# R40 register map
Vendor: Allwinner; Series: R40; File version: 0.1
CPU: CA7 0, little endian, MPU, FPU, double-precision FPU, 0 interrupt priority bits
Registers are 32-bit, read-write, reset 0x0 unless marked. A register's access mark holds for its fields unless they carry their own. Offsets are from the block's base; [hi:lo] are bit positions; lines under a group give offsets from that group; {n}, {i} and the like mark numbered series; 'fields as' and 'values as' point back to an identical list.

## TCON_TOP
Base 0x01C70000
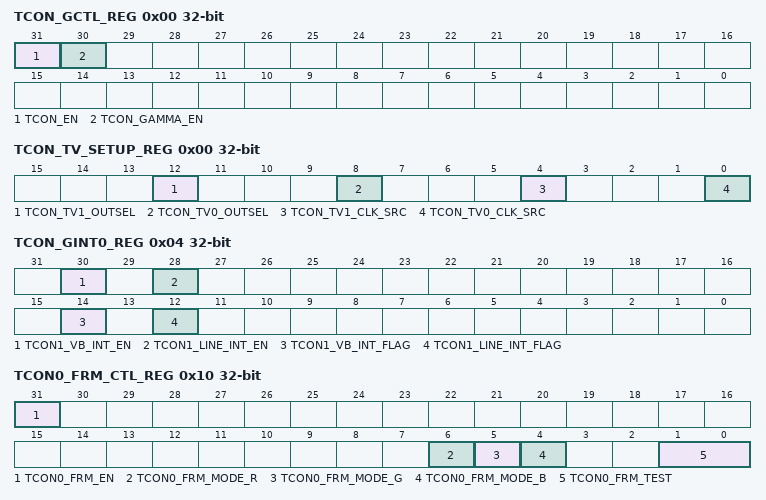
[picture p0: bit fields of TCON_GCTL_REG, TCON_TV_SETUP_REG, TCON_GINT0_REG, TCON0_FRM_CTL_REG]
0x00 TCON_GCTL_REG — TCON Global Control Register
  [31] TCON_EN — 0: Disable 1: Enable When it`s disabled, the module will be reset to idle state.
    0=Disable; 1=Enable When it`s disabled, the module will be reset to idle state
  [30] TCON_GAMMA_EN — 0: Disable 1: Enable
    0=Disable; 1=Enable
0x00 TCON_TV_SETUP_REG
  [12] TCON_TV1_OUTSEL — 0: LCD1 output to GPIOH 1: TV1 output to GPIOH
    0=LCD1 (LCD1 output to GPIOH); 1=TV1 (TV1 output to GPIOH)
  [8] TCON_TV0_OUTSEL — 0: LCD0 output to GPIOD 1: TV0 output to GPIOD
    0=LCD0 (LCD0 output to GPIOD); 1=TV0 (TV0 output to GPIOD)
  [4] TCON_TV1_CLK_SRC — 0: Clock from CCU 1: Clock from TVE1
    0=Clock_from_CCU; 1=Clock_from_TVE1
  [0] TCON_TV0_CLK_SRC — 0: Clock from CCU 1: Clock from TVE0
    0=Clock_from_CCU; 1=Clock_from_TVE0
0x04 TCON_GINT0_REG — TCON Global Interrupt Register0
  [30] TCON1_VB_INT_EN — 0: Disable 1: Enable
    0=Disable; 1=Enable
  [28] TCON1_LINE_INT_EN — 0: Disable 1: Enable
    0=Disable; 1=Enable
  [14] TCON1_VB_INT_FLAG — Asserted during vertical no-display period every frame. Write 0 to clear it.
  [12] TCON1_LINE_INT_FLAG — Trigger when SY1 match the current TCON1 scan line Write 0 to clear it.
0x08 TCON_GINT1_REG — TCON Global Interrupt Register1
  [11:0] TCON1_LINE_INT_NUM — scan line for TCON1 line trigger(including inactive lines) Setting it for the specified line for trigger 1. Note: SY1 is writable only when LINE_TRG1 disable.
0x10 TCON0_FRM_CTL_REG — TCON FRM Control Register
  [31] TCON0_FRM_EN — 0:Disable 1:Enable
  [6] TCON0_FRM_MODE_R — 0: 6bit frm output 1: 5bit frm output
    0=6bit frm output; 1=5bit frm output
  [5] TCON0_FRM_MODE_G — 0: 6bit frm output 1: 5bit frm output
    0=6bit frm output; 1=5bit frm output
  [4] TCON0_FRM_MODE_B — 0: 6bit frm output 1: 5bit frm output
    0=6bit frm output; 1=5bit frm output
  [1:0] TCON0_FRM_TEST — 00: FRM 01: half 5/6bit, half FRM 10: half 8bit, half FRM 11: half 8bit, half 5/6bit
{0x14+4i} TCON0_FRM_SEED_REG[{i}] (i=0..5) — TCON FRM Seed Register (N=0,1,2,3,4,5)
  [24:0] SEED_VALUE — N=0: Pixel_Seed_R N=1: Pixel_Seed_G N=2: Pixel_Seed_B N=3: Line_Seed_R N=4: Line_Seed_G N=5: Line_Seed_B Note: Avoid to set it to 0
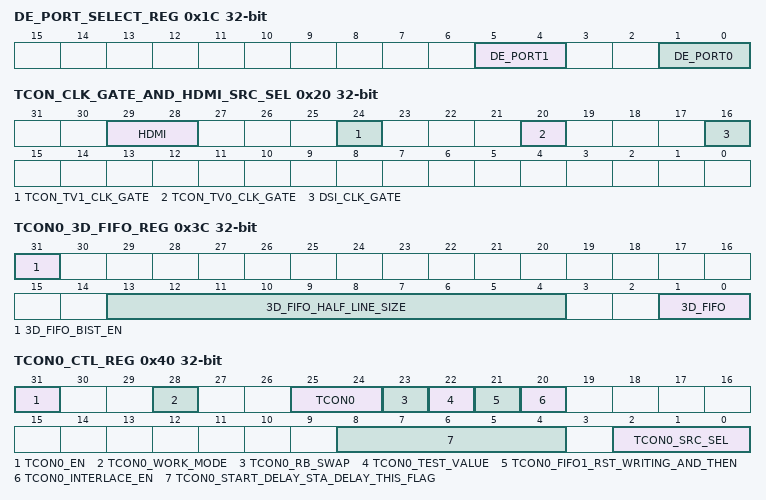
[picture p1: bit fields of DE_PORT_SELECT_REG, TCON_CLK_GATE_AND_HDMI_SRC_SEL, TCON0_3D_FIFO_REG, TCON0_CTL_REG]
0x1C DE_PORT_SELECT_REG
  [5:4] DE_PORT1 — PERH Select. 00:TCON_LCD0 01:TCON_LCD1 10:TCON_TV0 11:TCON_TV1 Note: The priority of DE0 is higher than DE1. If TCON_LCD0 selects DE0 and DE1 as source at the same time, then DE0 will be used for the source of TCON_LCD0.
  [1:0] DE_PORT0 — PERH Select. 00:TCON_LCD0 01:TCON_LCD1 10:TCON_TV0 11:TCON_TV1 Note: The priority of DE0 is higher than DE1. If TCON_LCD0 selects DE0 and DE1 as source at the same time, then DE0 will be used for the source of TCON_LCD0.
0x20 TCON_CLK_GATE_AND_HDMI_SRC_SEL
  [29:28] HDMI — Source select. 00:Disable 01:TCON_TV0 10:TCON_TV1 11:Reserved
  [24] TCON_TV1_CLK_GATE — 0:Disable clk 1:Enable clk
  [20] TCON_TV0_CLK_GATE — 0:Disable clk 1:Enable clk
  [16] DSI_CLK_GATE — 0:Disable clk 1:Enable clk
{0x2C+4i} TCON0_FRM_TAB_REG[{i}] (i=0..3) — TCON FRM Table Register (N=0,1,2,3)
  [31:0] FRM_TABLE_VALUE
0x3C TCON0_3D_FIFO_REG — TCON0 3D FIFO Register
  [31] 3D_FIFO_BIST_EN — 0: Disable 1: Enable
    0=Disable; 1=Enable
  [13:4] 3D_FIFO_HALF_LINE_SIZE — The number of data in half line=3D_FIFO_HALF_LINE_SIZE+1. Only valid when 3D_FIFO_SETTING set as 2
  [1:0] 3D_FIFO — 00: by pass 01: used as normal FIFO 10: used as 3D interlace FIFO 11: reserved
0x40 TCON0_CTL_REG — TCON0 Control Register
  [31] TCON0_EN — TCON0_EN 0: Disable 1: Enable Note: It executes at the beginning of the first blank line of TCON0 timing.
    0=Disable; 1=Enable Note: It executes at the beginning of the first blank line of TCON0 timing
  [28] TCON0_WORK_MODE — TCON0_WORK_MODE 0: Normal 1: Dynamic freq
    0=Normal; 1=Dynamic freq
  [25:24] TCON0 — TCON0_IF 00: HV(Sync+DE) 01: 8080 I/F 1x: Reservd
    0=HV_openingparen_Sync_plus_DE_closingparen_ (HV(Sync+DE)); 1=8080 I/F; 2=Reservd
  [23] TCON0_RB_SWAP — TCON0_RB_SWAP 0: Default 1: Swap RED and BLUE data at FIFO1
    0=Default; 1=Swap RED and BLUE data at FIFO1
  [22] TCON0_TEST_VALUE — TCON0_TEST_VALUE 0:all 0s 1:all 1s
  [21] TCON0_FIFO1_RST_WRITING_AND_THEN — TCON0_FIFO1_RST Writing 1 and then 0 at this bit will reset FIFO 1 Note: 1 holding time must more than 1 DCLK
  [20] TCON0_INTERLACE_EN — TCON0_INTERLACE_EN 0:Disable 1:Enable This flag is valid only when TCON0_EN = 1
  [8:4] TCON0_START_DELAY_STA_DELAY_THIS_FLAG — TCON0_START_DELAY STA delay This flag is valid only when TCON0_EN = 1
  [2:0] TCON0_SRC_SEL — TCON0_SRC_SEL 000: DE0 001: Color Check 010: Grayscale Check 011: Black by White Check 100: Test Data all 0 101: Test Data all 1 111: Gridding Check
0x40 TCON1_SRC_CTL_REG
  [2:0] TCON1_SRC_SEL — 000: DE 001: Color Check 010: Grayscale Check 011: Black by White Check 100: Reserved 101: Reserved 111: Gridding Check
    0=DE; 1=Color Check; 2=Grayscale Check; 3=Black by White Check; 7=Gridding Check
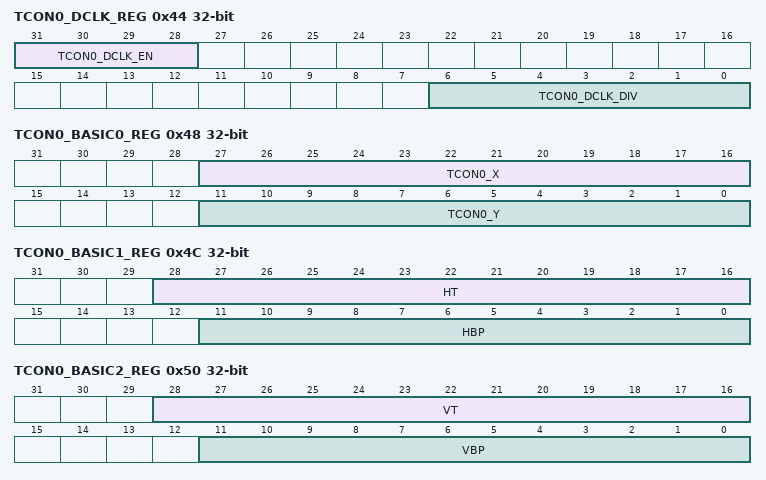
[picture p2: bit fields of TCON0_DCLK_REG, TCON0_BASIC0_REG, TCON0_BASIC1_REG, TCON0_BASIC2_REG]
0x44 TCON0_DCLK_REG — TCON0 Data Clock Register
  [31:28] TCON0_DCLK_EN — LCLK_EN[3:0] :TCON0 clock enable 4'h0, 'h4,4'h6,4'ha7:dclk_en=0;dclk1_en=0;dclk2_en=0;dclkm2_en=0; 4'h1: dclk_en = 1; dclk1_en = 0; dclk2_en = 0; dclkm2_en = 0; 4'h2: dclk_en = 1; dclk1_en = 0; dclk2_en = 0; dclkm2_en = 1; 4'h3: dclk_en = 1; dclk1_en = 1; dclk2_en = 0; dclkm2_en = 0; 4'h5: dclk_en = 1; dclk1_en = 0; dclk2_en = 1; dclkm2_en = 0; 4'h8,4'h9,4'ha,4'hb,4'hc,4'hd,4'he,4'hf: dclk_en = 1; dclk1_en = 1; dclk2_en = 1; dclkm2_en = 1;
  [6:0] TCON0_DCLK_DIV — Tdclk = Tsclk * DCLKDIV If dclk1&dclk2 used DCLKDIV >=6 If dclk only DCLKDIV >=1
0x48 TCON0_BASIC0_REG — TCON0 Basic Timing Register0
  [27:16] TCON0_X — Panel width is X+1
  [11:0] TCON0_Y — Panel height is Y+1
0x4C TCON0_BASIC1_REG — TCON0 Basic Timing Register1
  [28:16] HT — Thcycle = (HT+1) * Tdclk Computation 1) parallel:HT = X + BLANK Limitation: 1) parallel :HT >= (HBP +1) + (X+1) +2 2) serial 1: HT >= (HBP +1) + (X+1) *3+2 3) serial 2: HT >= (HBP +1) + (X+1) *3/2+2
  [11:0] HBP — horizontal back porch (in dclk) Thbp = (HBP +1) * Tdclk
0x50 TCON0_BASIC2_REG — TCON0 Basic Timing Register2
  [28:16] VT — TVT = (VT)/2 * Thsync Note: VT/2 >= (VBP+1 ) + (Y+1) +2
  [11:0] VBP — Tvbp = (VBP +1) * Thsync
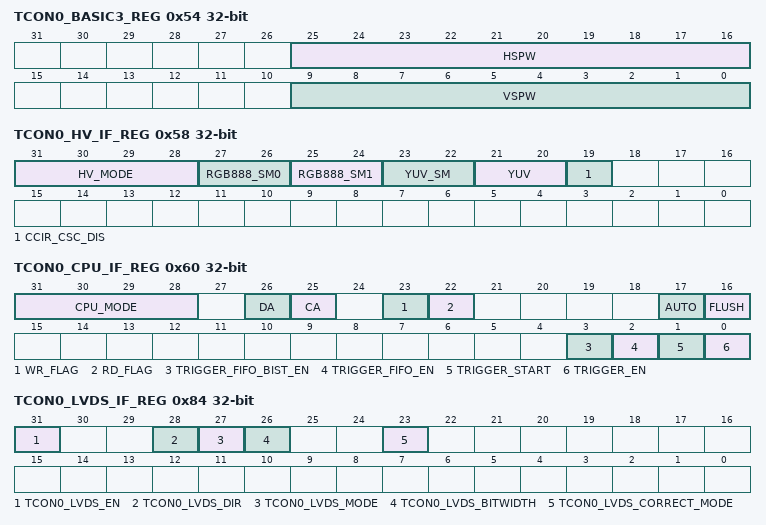
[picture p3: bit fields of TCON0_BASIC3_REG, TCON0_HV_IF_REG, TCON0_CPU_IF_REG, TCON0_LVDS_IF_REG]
0x54 TCON0_BASIC3_REG — TCON0 Basic Timing Register3
  [25:16] HSPW — Thspw = (HSPW+1) * Tdclk Note: HT> (HSPW+1)
  [9:0] VSPW — Tvspw = (VSPW+1) * Thsync Note: VT/2 > (VSPW+1)
0x58 TCON0_HV_IF_REG — TCON0 HV Panel Interface Register
  [31:28] HV_MODE — 0000: 24bit/1cycle parallel mode 1000: 8bit/3cycle RGB serial mode(RGB888) 1010: 8bit/4cycle Dummy RGB(DRGB) 1011: 8bit/4cycle RGB Dummy(RGBD) 1100: 8bit/2cycle YUV serial mode(CCIR656)
    0=_24bit_slash_1cycle_parallel_mode (24bit/1cycle parallel mode); 8=_8bit_slash_3cycle_RGB (8bit/3cycle RGB serial mode(RGB888)); 10=_8bit_slash_4cycle_Dummy (8bit/4cycle Dummy RGB(DRGB)); 11=_8bit_slash_4cycle_RGB (8bit/4cycle RGB Dummy(RGBD)); 12=_8bit_slash_2cycle_YUV (8bit/2cycle YUV serial mode(CCIR656))
  [27:26] RGB888_SM0 — serial RGB888 mode output sequence at odd lines of the panel (line 1, 3, 5, 7...) 00: R→G→B 01: B→R→G 10: G→B→R 11: R→G→B
  [25:24] RGB888_SM1 — serial RGB888 mode output sequence at even lines of the panel (line 2, 4, 6, 8...) 00: R→G→B 01: B→R→G 10: G→B→R 11: R→G→B
  [23:22] YUV_SM — serial YUV mode output sequence 2-pixel-pair of every scan line 00: YUYV 01: YVYU 10: UYVY 11: VYUY
    0=YUYV; 1=YVYU; 2=UYVY; 3=VYUY
  [21:20] YUV — EAV/SAV F LINE DELAY 00:F toggle right after active video line 01:delay 2 line(CCIR PAL) 10:delay 3 line(CCIR NTSC) 11:reserved
  [19] CCIR_CSC_DIS — 0: Enable 1: Disable Only valid when HV mode is `1100`, select `0` TCON convert source from RGB to YUV
    0=Enable; 1=Disable Only valid when HV mode is `1100`, select `0` TCON convert source from RGB to YUV
0x60 TCON0_CPU_IF_REG — TCON0 CPU Panel Interface Register
  [31:28] CPU_MODE — 0000: 18bit/256K mode 0010: 16bit mode0 0100: 16bit mode1 0110: 16bit mode2 1000: 16bit mode3 1010: 9bit mode 1100: 8bit 256K mode 1110: 8bit 65K mode xxx1: 24bit for DSI
    0=_18bit_slash_256K_mode (18bit/256K mode); 2=_16bit_mode0; 4=_16bit_mode1; 6=_16bit_mode2; 8=_16bit_mode3; 10=_9bit_mode; 12=_8bit_256K_mode; 14=_8bit_65K_mode; 1=24bit for DSI
  [26] DA — pin A1 value in 8080 mode auto/flash states
  [25] CA — pin A1 value in 8080 mode WR/RD execute
  [23] WR_FLAG ro — 0:Write operation is finishing 1:Write operation is pending
  [22] RD_FLAG ro — 0:Read operation is finishing 1:Read operation is pending
  [17] AUTO — auto Transfer Mode: If it is 1, all the valid data during this frame are written to panel. Note: This bit is sampled by Vsync
  [16] FLUSH — direct transfer mode If it is enabled, FIFO1 is regardless of the HV timing, pixels data keep being transferred unless the input FIFO was empty. Data output rate control by DCLK.
  [3] TRIGGER_FIFO_BIST_EN — 0: Disable 1: Enable Entry addr is 0xFF8
    0=Disable; 1=Enable Entry addr is 0xFF8
  [2] TRIGGER_FIFO_EN — 0:Enable 1:Disable
  [1] TRIGGER_START write-1-sets — Write `1` to start a frame flush, writing`0` has no effect. This flag indicated frame flush is running. Software must make sure that write `1` only when this flag is `0`.
  [0] TRIGGER_EN — 0: Trigger mode disable 1: Trigger mode enable
    0=disable (Trigger mode disable); 1=enable (Trigger mode enable)
0x64 TCON0_CPU_WRITE_REG — TCON0 CPU Panel Write Data Register
  [23:0] DATA_WRITE wo — Data write on 8080 bus, launch a write operation on 8080 bus
0x68 TCON0_CPU_RD0_REG — TCON0 CPU Panel Read Data Register0
  [23:0] DATA_READ0 ro — Data read on 8080 bus, launch a new read operation on 8080 bus
0x6C TCON0_CPU_RD1_REG — TCON0 CPU Panel Read Data Register1
  [23:0] DATA_READ1 ro — Data_READ1 Data read on 8080 bus, without a new read operation on 8080 bus
0x84 TCON0_LVDS_IF_REG
  [31] TCON0_LVDS_EN — 0: Disable 1: Enable
    0=Disable; 1=Enable
  [28] TCON0_LVDS_DIR — 1: Normal 2: Reversed Note: LVDS direction
    1=Normal
  [27] TCON0_LVDS_MODE — 0: NS mode 1: JEIDA mode
    0=NS_mode; 1=JEIDA_mode
  [26] TCON0_LVDS_BITWIDTH — 0: 24bit 1: 18bit
    0=_24bit; 1=_18bit
  [23] TCON0_LVDS_CORRECT_MODE — 0: Mode0 1: Mode1
    0=Mode0; 1=Mode1
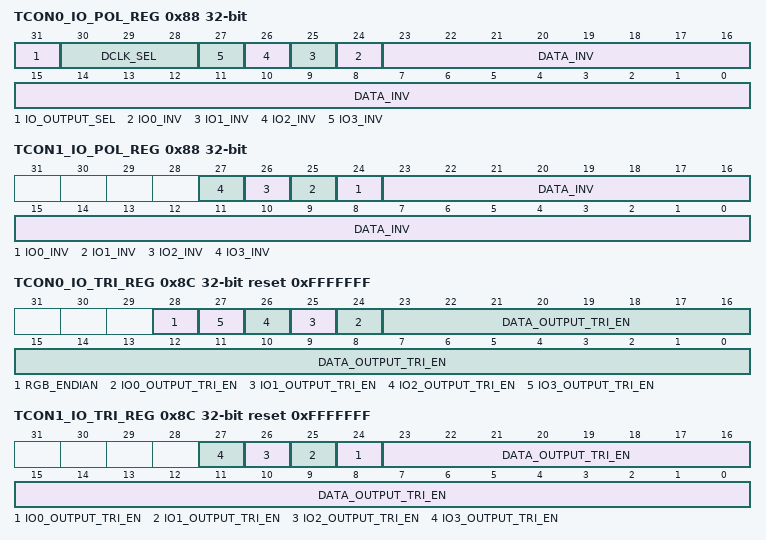
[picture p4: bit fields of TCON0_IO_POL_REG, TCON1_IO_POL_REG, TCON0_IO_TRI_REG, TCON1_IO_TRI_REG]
0x88 TCON0_IO_POL_REG — TCON0 IO Polarity Register
  [31] IO_OUTPUT_SEL — 0: normal output 1: register output when set as `1`, d*23:0+, io0, io1,io3 sync to dclk
    0=normal output; 1=register output when set as `1`, d*23:0+, io0, io1,io3 sync to dclk
  [30:28] DCLK_SEL — 000: used DCLK0(normal phase offset) 001: used DCLK1(1/3 phase offset) 010: used DCLK2(2/3 phase offset) 101: DCLK0/2 phase 0 100: DCLK0/2 phase 90 Others: Reserved
    0=used_DCLK0_openingparen_normal_phase (used DCLK0(normal phase offset)); 1=used_DCLK1_openingparen_1_slash_3_phase (used DCLK1(1/3 phase offset)); 2=used_DCLK2_openingparen_2_slash_3_phase (used DCLK2(2/3 phase offset)); 5=DCLK0_slash_2_phase_0 (DCLK0/2 phase 0); 4=DCLK0_slash_2_phase_90 (DCLK0/2 phase 90 Others: Reserved)
  [n+24] IO{n}_INV (n=0..3) — 0: not invert 1: invert
    0=not_invert; 1=invert
  [23:0] DATA_INV — TCON0 output port D[23:0] polarity control, with independent bit control: 0s: normal polarity 1s: invert the specify output
0x88 TCON1_IO_POL_REG — TCON1 IO Polarity Register
  [n+24] IO{n}_INV (n=0..3) — 0: not invert 1: invert
    0=not_invert; 1=invert
  [23:0] DATA_INV — TCON1 output port D[23:0] polarity control, with independent bit control: 0s: normal polarity 1s: invert the specify output
0x8C TCON0_IO_TRI_REG reset 0xFFFFFFF — TCON0 IO Control Register
  [28] RGB_ENDIAN — 0: Normal 1: Bits_invert
    0=Normal; 1=Bits_invert
  [n+24] IO{n}_OUTPUT_TRI_EN (n=0..3) — 1: Disable 0: Enable
    1=Disable; 0=Enable
  [23:0] DATA_OUTPUT_TRI_EN — TCON0 output port D[23:0] output enable, with independent bit control: 1s: Disable 0s: Enable
0x8C TCON1_IO_TRI_REG reset 0xFFFFFFF — TCON1 IO Control Register
  [n+24] IO{n}_OUTPUT_TRI_EN (n=0..3) — 1: Disable 0: Enable
    1=Disable; 0=Enable
  [23:0] DATA_OUTPUT_TRI_EN — TCON1 output port D[23:0] output enable, with independent bit control: 1s: Disable 0s: Enable
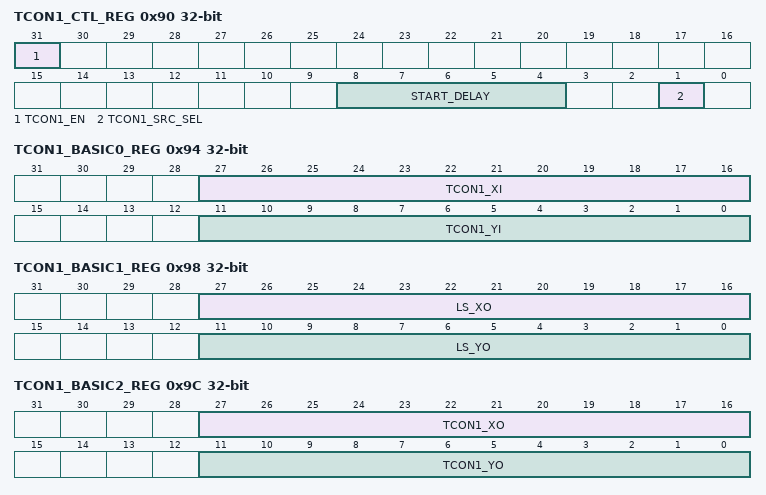
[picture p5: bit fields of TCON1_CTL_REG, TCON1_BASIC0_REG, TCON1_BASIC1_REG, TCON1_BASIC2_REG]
0x90 TCON1_CTL_REG — TCON1 Control Register
  [31] TCON1_EN — 0: Disable 1: Enable
    0=Disable; 1=Enable
  [8:4] START_DELAY — This is for DE0 and DE1
  [1] TCON1_SRC_SEL — 0: Reserved 1: BLUE data(FIFO2 disable, RGB=0000FF) Note The priority of the bit is higher than .
    1=BLUE (BLUE data(FIFO2 disable, RGB=0000FF) Note The priority of the bit is higher than .)
0x94 TCON1_BASIC0_REG — TCON1 Basic Timing Register0
  [27:16] TCON1_XI — source width is X+1
  [11:0] TCON1_YI — source height is Y+1
0x98 TCON1_BASIC1_REG — TCON1 Basic Timing Register1
  [27:16] LS_XO — width is LS_XO+1
  [11:0] LS_YO — width is LS_YO+1 This version LS_YO = TCON1_YI
0x9C TCON1_BASIC2_REG — TCON1 Basic Timing Register2
  [27:16] TCON1_XO — width is TCON1_XO+1
  [11:0] TCON1_YO — height is TCON1_YO+1
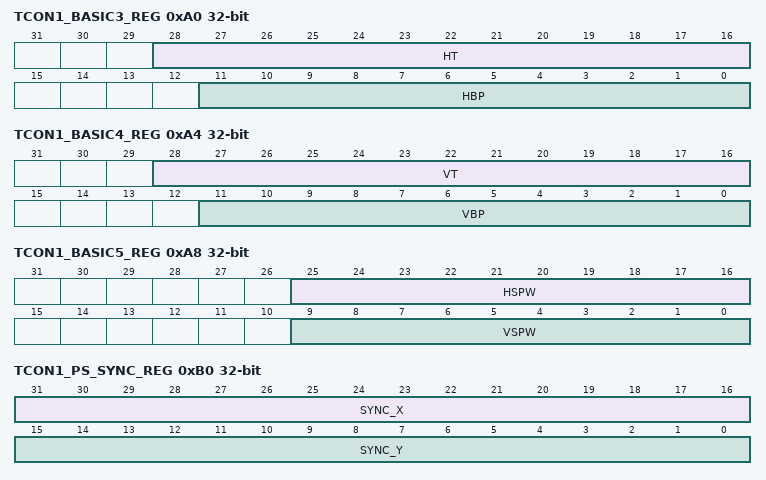
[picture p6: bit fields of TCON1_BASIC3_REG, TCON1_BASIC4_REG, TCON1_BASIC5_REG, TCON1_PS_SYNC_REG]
0xA0 TCON1_BASIC3_REG — TCON1 Basic Timing Register3
  [28:16] HT — horizontal total time Thcycle = (HT+1) * Thdclk
  [11:0] HBP — horizontal back porch Thbp = (HBP +1) * Thdclk
0xA4 TCON1_BASIC4_REG — TCON1 Basic Timing Register4
  [28:16] VT — horizontal total time (in HD line) Tvt = VT/2 * Th
  [11:0] VBP — horizontal back porch (in HD line) Tvbp = (VBP +1) * Th
0xA8 TCON1_BASIC5_REG — TCON1 Basic Timing Register5
  [25:16] HSPW — horizontal Sync Pulse Width (in dclk) Thspw = (HSPW+1) * Tdclk Note: HT > (HSPW+1)
  [9:0] VSPW — vertical Sync Pulse Width (in lines) Tvspw = (VSPW+1) * Th Note: VT/2 > (VSPW+1)
0xB0 TCON1_PS_SYNC_REG — TCON1 Sync Register
  [31:16] SYNC_X, [15:0] SYNC_Y
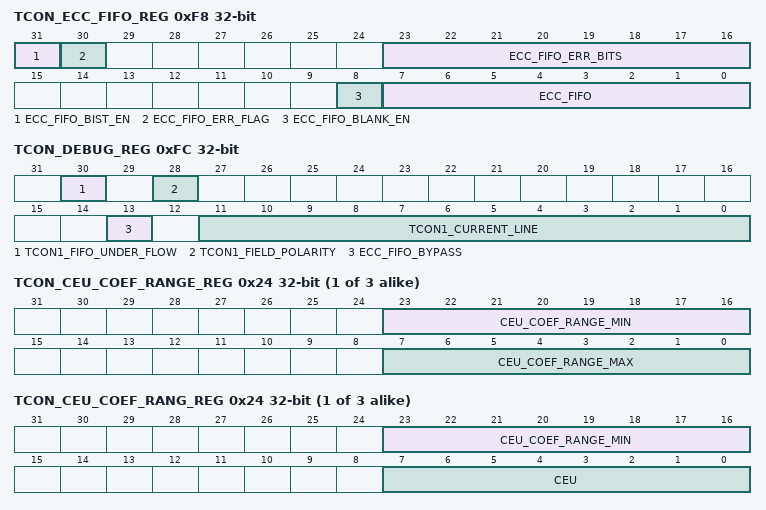
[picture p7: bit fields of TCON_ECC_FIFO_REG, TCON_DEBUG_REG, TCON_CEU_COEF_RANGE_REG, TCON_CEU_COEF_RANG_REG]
0xF8 TCON_ECC_FIFO_REG reset not defined — TCON ECC FIFO Register
  [31] ECC_FIFO_BIST_EN — 0: Disable 1: Enable
    0=Disable; 1=Enable
  [30] ECC_FIFO_ERR_FLAG
  [23:16] ECC_FIFO_ERR_BITS
  [8] ECC_FIFO_BLANK_EN — 0: Disable ecc function in blanking 1: Enable ecc function in blanking ECC function is tent to trigger in blanking area at hv mode, set `0` when in hv mode
    0=Disable ecc function in blanking; 1=Enable ecc function in blanking ECC function is tent to trigger in blanking area at hv mode, set `0` when in hv mode
  [7:0] ECC_FIFO — bit3 0:Enable 1:Disable
0xFC TCON_DEBUG_REG (reset mask 0x2000) — TCON Debug Register
  [30] TCON1_FIFO_UNDER_FLOW
  [28] TCON1_FIELD_POLARITY ro — 0: second field 1: first field
    0=second; 1=first
  [13] ECC_FIFO_BYPASS — 0: used 1: bypass
    0=used; 1=bypass
  [11:0] TCON1_CURRENT_LINE ro
0x100 TCON_CEU_CTL_REG — TCON CEU Control Register
  [31] CEU_EN — 0: bypass 1: enable
    0=bypass; 1=enable
{0x110+4i} TCON_CEU_COEF_MUL_REG_{i} (i=0..2) — N*0x04 TCON CEU Coefficient Register0 (N=0,1,2,4,5,6,8,9,10)
  [12:0] CEU_COEF_MUL_VALUE — signed 13bit value, range of (-16,16) N=0: Rr N=1: Rg N=2: Rb N=4: Gr N=5: Gg N=6: Gb N=8: Br N=9: Bg N=10: Bb
{0x11C+0xC*i} _N[{i}] (i=0..2) group
  0x00 TCON_CEU_COEF_ADD_REG — TCON CEU Coefficient Register1 (N=0,1,2)
    [18:0] CEU_COEF_ADD_VALUE — signed 19bit value, range of (-16384, 16384) N=0: Rc N=1: Gc N=2: Bc
  0x24 TCON_CEU_COEF_RANGE_REG
    [23:16] CEU_COEF_RANGE_MIN — unsigned 8bit value, range of [0,255]
    [7:0] CEU_COEF_RANGE_MAX — unsigned 8bit value, range of [0,255]
  0x24 TCON_CEU_COEF_RANG_REG — TCON CEU Coefficient Register2 (N=0,1,2)
    [23:16] CEU_COEF_RANGE_MIN — Unsigned 8bit value, range of [0,255]
    [7:0] CEU — COEF_RANGE_MAX Unsigned 8bit value, range of [0,255]
  0x1E8 TCON1_FILL_BEGIN_REG — TCON1 Fill Data Begin Register (N=0,1,2)
    [23:0] FILL_BEGIN
  0x1EC TCON1_FILL_END_REG — TCON1 Fill Data End Register (N=0,1,2)
    [23:0] FILL_END
  0x1F0 TCON1_FILL_DATA0_REG — TCON1 Fill Data Value Register (N=0,1,2)
    [23:0] FILL_VALUE
{0x110+4i} TCON_CEU_COEF_MUL_REG_{i} (i=4..6) — N*0x04 TCON CEU Coefficient Register0 (N=0,1,2,4,5,6,8,9,10)
  fields as TCON_CEU_COEF_MUL_REG_0
{0x110+4i} TCON_CEU_COEF_MUL_REG_{i} (i=8..10) — N*0x04 TCON CEU Coefficient Register0 (N=0,1,2,4,5,6,8,9,10)
  fields as TCON_CEU_COEF_MUL_REG_0
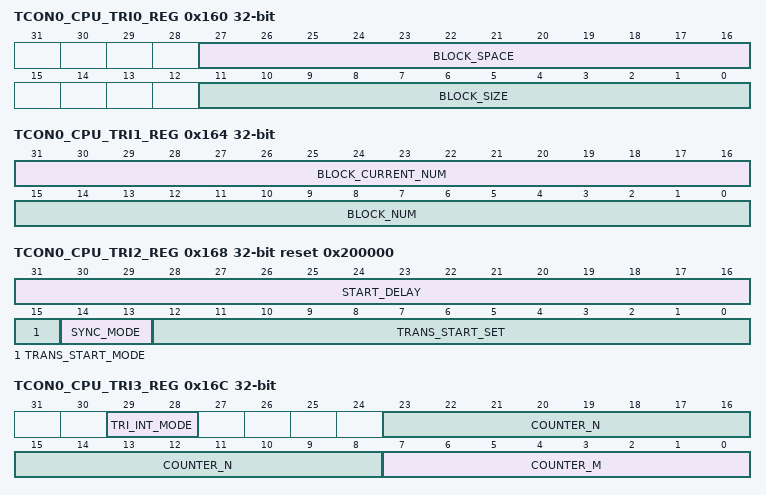
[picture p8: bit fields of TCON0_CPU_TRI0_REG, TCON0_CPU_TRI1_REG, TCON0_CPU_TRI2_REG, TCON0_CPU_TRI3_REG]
0x160 TCON0_CPU_TRI0_REG — TCON0 CPU Panel Trigger Register0
  [27:16] BLOCK_SPACE — should be set >20*pixel_cycle
  [11:0] BLOCK_SIZE
0x164 TCON0_CPU_TRI1_REG — TCON0 CPU Panel Trigger Register1
  [31:16] BLOCK_CURRENT_NUM ro, [15:0] BLOCK_NUM
0x168 TCON0_CPU_TRI2_REG reset 0x200000 — TCON0 CPU Panel Trigger Register2
  [31:16] START_DELAY — Tdly = (Start_Delay +1) * be_clk*8
  [15] TRANS_START_MODE — 0: ecc_fifo+tri_fifo 1: tri_fifo
    0=ecc_fifo_plus_tri_fifo (ecc_fifo+tri_fifo); 1=tri_fifo
  [14:13] SYNC_MODE — 0x: auto 10: 0 11: 1
    2=_0; 3=_1
  [12:0] TRANS_START_SET
0x16C TCON0_CPU_TRI3_REG — TCON0 CPU Panel Trigger Register3
  [29:28] TRI_INT_MODE — 00: disable 01: counter mode 10: te rising mode 11: te falling mode when set as 01, Tri_Counter_Int occur in cycle of (Count_N+1)×(Count_M+1)×4 dclk. when set as 10 or 11, io0 is map as TE input.
  [23:8] COUNTER_N
  [7:0] COUNTER_M
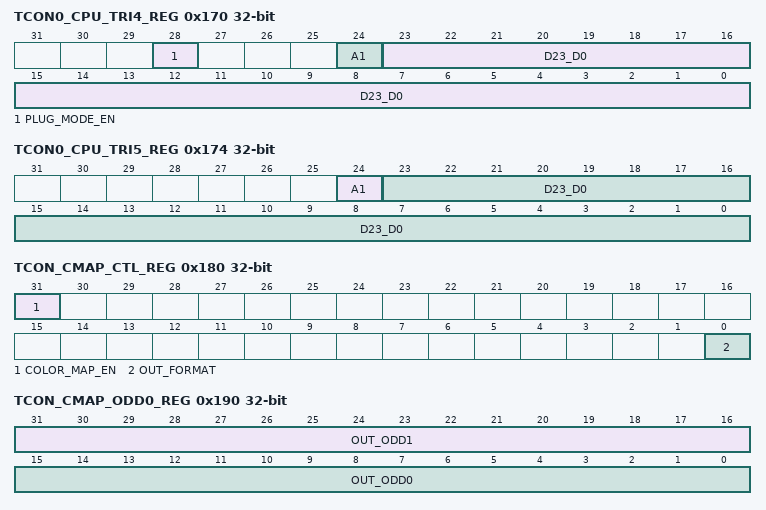
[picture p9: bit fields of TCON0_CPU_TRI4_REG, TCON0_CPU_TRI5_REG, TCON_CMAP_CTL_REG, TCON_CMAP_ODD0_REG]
0x170 TCON0_CPU_TRI4_REG — TCON0 CPU Panel Trigger Register4
  [28] PLUG_MODE_EN — 0: Disable 1: Enable
    0=Disable; 1=Enable
  [24] A1 — Valid in first Block
  [23:0] D23_D0 — Valid in first Block
0x174 TCON0_CPU_TRI5_REG — TCON0 CPU Panel Trigger Register5
  [24] A1 — Valid in Block except first
  [23:0] D23_D0 — Valid in Block except first
0x180 TCON_CMAP_CTL_REG — TCON Color Map Control register
  [31] COLOR_MAP_EN — 0: bypass 1: enable This module only work when X is divided by 4
    0=bypass; 1=enable This module only work when X is divided by 4
  [0] OUT_FORMAT — 0: 4 pixel output mode: Out0 -> Out1 -> Out2 -> Out3 1: 2 pixel output mode: Out0 -> Out1
    0=4 pixel output mode: Out0 -> Out1 -> Out2 -> Out3; 1=2 pixel output mode: Out0 -> Out1
0x190 TCON_CMAP_ODD0_REG — TCON Color Map Odd Line Register0
  [31:16] OUT_ODD1
  [15:0] OUT_ODD0 — bit15-12: Reserved bit11-08: Out_Odd0[23:16] bit07-04: Out_Odd0[15:8] bit03-00: Out_Odd0[7:0] 0x0: in_b0 0x1: in_g0 0x2: in_r0 0x3: Reserved 0x4: in_b1 0x5: in_g1 0x6: in_r1 0x7: Reserved 0x8: in_b2 0x9: in_g2GIC 0xa: in_r2 0xb: Reserved 0xc: in_b3 0xd: in_g3 0xe: in_r3 0xf: Reserved
    0=in_b0; 1=in_g0; 2=in_r0; 4=in_b1; 5=in_g1; 6=in_r1; 8=in_b2; 9=in_g2GIC 0xa: in_r2 0xb: Reserved 0xc: in_b3 0xd: in_g3 0xe: in_r3 0xf: Reserved
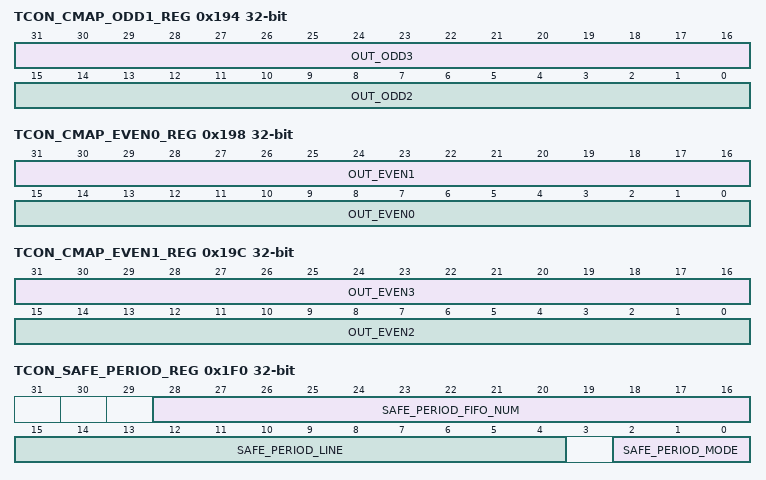
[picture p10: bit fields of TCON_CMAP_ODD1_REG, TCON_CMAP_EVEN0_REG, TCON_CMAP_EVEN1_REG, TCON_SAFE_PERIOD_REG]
0x194 TCON_CMAP_ODD1_REG — TCON Color Map Odd Line Register1
  [31:16] OUT_ODD3, [15:0] OUT_ODD2
0x198 TCON_CMAP_EVEN0_REG — TCON Color Map Even Line Register0
  [31:16] OUT_EVEN1, [15:0] OUT_EVEN0
0x19C TCON_CMAP_EVEN1_REG — TCON Color Map Even Line Register1
  [31:16] OUT_EVEN3, [15:0] OUT_EVEN2
0x1F0 TCON_SAFE_PERIOD_REG — TCON Safe Period Register
  [28:16] SAFE_PERIOD_FIFO_NUM
  [15:4] SAFE_PERIOD_LINE
  [2:0] SAFE_PERIOD_MODE — 000: unsafe 001: safe 010: safe at ecc_fifo_curr_num > safe_period_fifo_num 011: safe at 2 and safe at sync active 100: safe at line
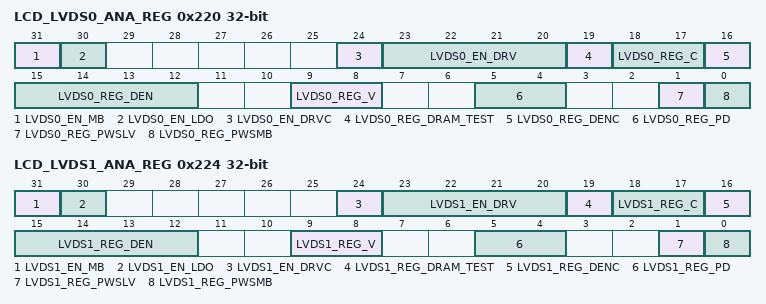
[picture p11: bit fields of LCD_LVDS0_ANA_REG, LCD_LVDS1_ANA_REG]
0x220 LCD_LVDS0_ANA_REG
  [31] LVDS0_EN_MB — Enable the bias circuit of the LVDS_Ana module
  [30] LVDS0_EN_LDO
  [24] LVDS0_EN_DRVC — Enable all circuits working when transmitting the data in channel clock of LVDS_tx0
  [23:20] LVDS0_EN_DRV — Enable all circuits working when transmitting the data in channel<3:0> of LVDS_tx0
  [19] LVDS0_REG_DRAM_TEST — 0:dram test clk disable 1:dram test clk enable
  [18:17] LVDS0_REG_C — Adjust current flowing through Rload of Rx to change the differential signals amplitude 00:250mV 01:300mV 10:350mV 11:400mV
  [16] LVDS0_REG_DENC — Choose data output or PLL test clock output in LVDS_tx
  [15:12] LVDS0_REG_DEN — Choose data output or PLL test clock output in LVDS_tx
  [9:8] LVDS0_REG_V — Adjust common mode voltage of the differential signals in five channels. single signal high level: 00:1.1V 01:1.19V 10:1.3V 11:1.43V
  [5:4] LVDS0_REG_PD — Fine adjust the slew rate of output data
  [1] LVDS0_REG_PWSLV — Adjust voltage amplitude of low power in LVDS_Ana
  [0] LVDS0_REG_PWSMB — Adjust voltage amplitude of mbias voltage reference in LVDS_Ana
0x224 LCD_LVDS1_ANA_REG
  [31] LVDS1_EN_MB — Enable the bias circuit of the LVDS_Ana module
  [30] LVDS1_EN_LDO
  [24] LVDS1_EN_DRVC — Enable all circuits working when transmitting the data in channel clock of LVDS_tx0
  [23:20] LVDS1_EN_DRV — Enable all circuits working when transmitting the data in channel<3:0> of LVDS_tx0
  [19] LVDS1_REG_DRAM_TEST — 0:dram test clk disable 1:dram test clk enable
  [18:17] LVDS1_REG_C — Adjust current flowing through Road of Rx to change the differential signals amplitude 00:250mV 01:300mV 10:350mV 11:400mV
  [16] LVDS1_REG_DENC — Choose data output or PLL test clock output in LVDS_tx
  [15:12] LVDS1_REG_DEN — Choose data output or PLL test clock output in LVDS_tx
  [9:8] LVDS1_REG_V — Adjust common mode voltage of the differential signals in five channels. single signal high level: 00:1.1V 01:1.19V 10:1.3V 11:1.43V
  [5:4] LVDS1_REG_PD — Fine adjust the slew rate of output data
  [1] LVDS1_REG_PWSLV — Adjust voltage amplitude of low power in LVDS_Ana
  [0] LVDS1_REG_PWSMB — Adjust voltage amplitude of mbias voltage reference in LVDS_Ana
0x300 TCON1_FILL_CTL_REG — TCON1 Fill Data Control Register
  [31] TCON1_FILL_EN — 0: bypass 1: enable
    0=bypass; 1=enable

## TCON_LCD0
Base 0x01C71000
Same registers: TCON_LCD1 0x01C72000
Registers as TCON_TOP, without TCON_TV_SETUP_REG, DE_PORT_SELECT_REG, TCON_CLK_GATE_AND_HDMI_SRC_SEL, TCON1_SRC_CTL_REG, TCON0_LVDS_IF_REG, TCON1_IO_POL_REG, TCON1_IO_TRI_REG, TCON1_CTL_REG, TCON1_BASIC{n}_REG (n=0..5), TCON1_PS_SYNC_REG, TCON_ECC_FIFO_REG, _N[*], LCD_LVDS0_ANA_REG, LCD_LVDS1_ANA_REG, TCON1_FILL_CTL_REG; these are added or differ:
{0x11C+0x10*i} _N[{i}] (i=0..2) group
  0x00 TCON_CEU_COEF_ADD_REG — TCON CEU Coefficient Register1 (N=0,1,2)
    [18:0] CEU_COEF_ADD_VALUE — signed 19bit value, range of (-16384, 16384) N=0: Rc N=1: Gc N=2: Bc
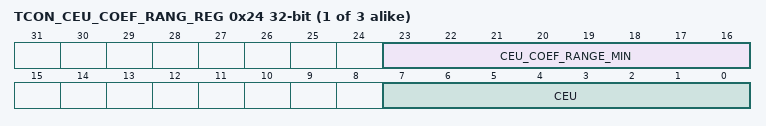
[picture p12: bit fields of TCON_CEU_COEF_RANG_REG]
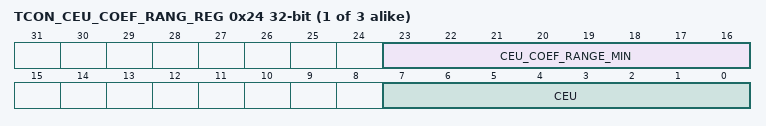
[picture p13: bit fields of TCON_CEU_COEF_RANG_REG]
  0x24 TCON_CEU_COEF_RANG_REG — TCON CEU Coefficient Register2 (N=0,1,2)
    [23:16] CEU_COEF_RANGE_MIN — Unsigned 8bit value, range of [0,255]
    [7:0] CEU — COEF_RANGE_MAX Unsigned 8bit value, range of [0,255]

## TCON_TV0
Base 0x01C73000
Same registers: TCON_TV1 0x01C74000
Registers as TCON_TOP, without TCON_TV_SETUP_REG, TCON0_FRM_CTL_REG, TCON0_FRM_SEED_REG[*], DE_PORT_SELECT_REG, TCON_CLK_GATE_AND_HDMI_SRC_SEL, TCON0_FRM_TAB_REG[*], TCON0_3D_FIFO_REG, TCON0_CTL_REG, TCON1_SRC_CTL_REG, TCON0_DCLK_REG, TCON0_BASIC{n}_REG (n=0..3), TCON0_HV_IF_REG, TCON0_CPU_IF_REG, TCON0_CPU_WRITE_REG, TCON0_CPU_RD0_REG, TCON0_CPU_RD1_REG, TCON0_LVDS_IF_REG, TCON0_IO_POL_REG, TCON0_IO_TRI_REG, TCON0_CPU_TRI{n}_REG (n=0..5), TCON_CMAP_CTL_REG, TCON_CMAP_ODD0_REG, TCON_CMAP_ODD1_REG, TCON_CMAP_EVEN0_REG, TCON_CMAP_EVEN1_REG, LCD_LVDS0_ANA_REG, LCD_LVDS1_ANA_REG; these are added or differ:
{0x11C+0xC*i} _N[{i}] (i=0..2) group
  0x00 TCON_CEU_COEF_ADD_REG — TCON CEU Coefficient Register1 (N=0,1,2)
    [18:0] CEU_COEF_ADD_VALUE — signed 19bit value, range of (-16384, 16384) N=0: Rc N=1: Gc N=2: Bc
  0x24 TCON_CEU_COEF_RANG_REG — TCON CEU Coefficient Register2 (N=0,1,2)
    [23:16] CEU_COEF_RANGE_MIN — Unsigned 8bit value, range of [0,255]
    [7:0] CEU — COEF_RANGE_MAX Unsigned 8bit value, range of [0,255]
  0x1E8 TCON1_FILL_BEGIN_REG — TCON1 Fill Data Begin Register (N=0,1,2)
    [23:0] FILL_BEGIN
  0x1EC TCON1_FILL_END_REG — TCON1 Fill Data End Register (N=0,1,2)
    [23:0] FILL_END
  0x1F0 TCON1_FILL_DATA0_REG — TCON1 Fill Data Value Register (N=0,1,2)
    [23:0] FILL_VALUE
